[part 1 of 2: packages /MICROSAR/NvM_swc/DataTypes to /MICROSAR/NvM_swc/ComponentTypes]
AUTOSAR XML (schema 00044)
package /MICROSAR/NvM_swc/DataTypes
  impl type NvM_RequestResultType: compu {0=NVM_REQ_OK, 1=NVM_REQ_NOT_OK, 2=NVM_REQ_PENDING, 3=NVM_REQ_INTEGRITY_FAILED, 4=NVM_REQ_BLOCK_SKIPPED, 5=NVM_REQ_NV_INVALIDATED, 6=NVM_REQ_CANCELED, 7=NVM_REQ_REDUNDANCY_FAILED, 8=NVM_REQ_RESTORED_FROM_ROM}, range raw 0..8, implementation-data-type=uint8
  impl type NvM_BlockIdType: range raw 1..32767, implementation-data-type=uint16
  impl type NvM_ServiceIdType: compu {6=NVM_READ_BLOCK, 7=NVM_WRITE_BLOCK, 8=NVM_RESTORE_BLOCK_DEFAULTS, 9=NVM_ERASE_BLOCK, 11=NVM_INVALIDATE_NV_BLOCK, 12=NVM_READ_ALL}, range raw 6..12, implementation-data-type=uint8
package /MICROSAR/NvM_swc/Interfaces
  client server interface NvMAdministration: is-service=true, service-kind=NON-VOLATILE-RAM-MANAGER
    operation SetBlockProtection: possible-error=NvMAdministration/E_NOT_OK
      arg ProtectionEnabled: type=boolean, direction=IN
    error E_NOT_OK: error-code=1
  client server interface NvMService_AC3_SRBS_DS_Defs: is-service=true, service-kind=NON-VOLATILE-RAM-MANAGER
    9 x operation, all with possible-error=NvMService_AC3_SRBS_DS_Defs/E_NOT_OK:
      GetErrorStatus
        arg ErrorStatus: type=NvM_RequestResultType, direction=OUT
      SetRamBlockStatus
        arg RamBlockStatus: type=boolean, direction=IN
      ReadBlock
        arg DstPtr: type=dtRef_VOID, direction=IN
      WriteBlock
        arg SrcPtr: type=dtRef_const_VOID, direction=IN
      RestoreBlockDefaults
        arg DstPtr: type=dtRef_VOID, direction=IN
      SetDataIndex
        arg DataIndex: type=uint8, direction=IN
      GetDataIndex
        arg DataIndex: type=uint8, direction=OUT
      InvalidateNvBlock
      EraseBlock
    error E_NOT_OK: error-code=1
  client server interface NvMNotifyJobFinished: is-service=true, service-kind=NON-VOLATILE-RAM-MANAGER
    operation JobFinished
      arg ServiceId: type=NvM_ServiceIdType, direction=IN
      arg JobResult: type=NvM_RequestResultType, direction=IN
package /MICROSAR/NvM_swc/ComponentTypes
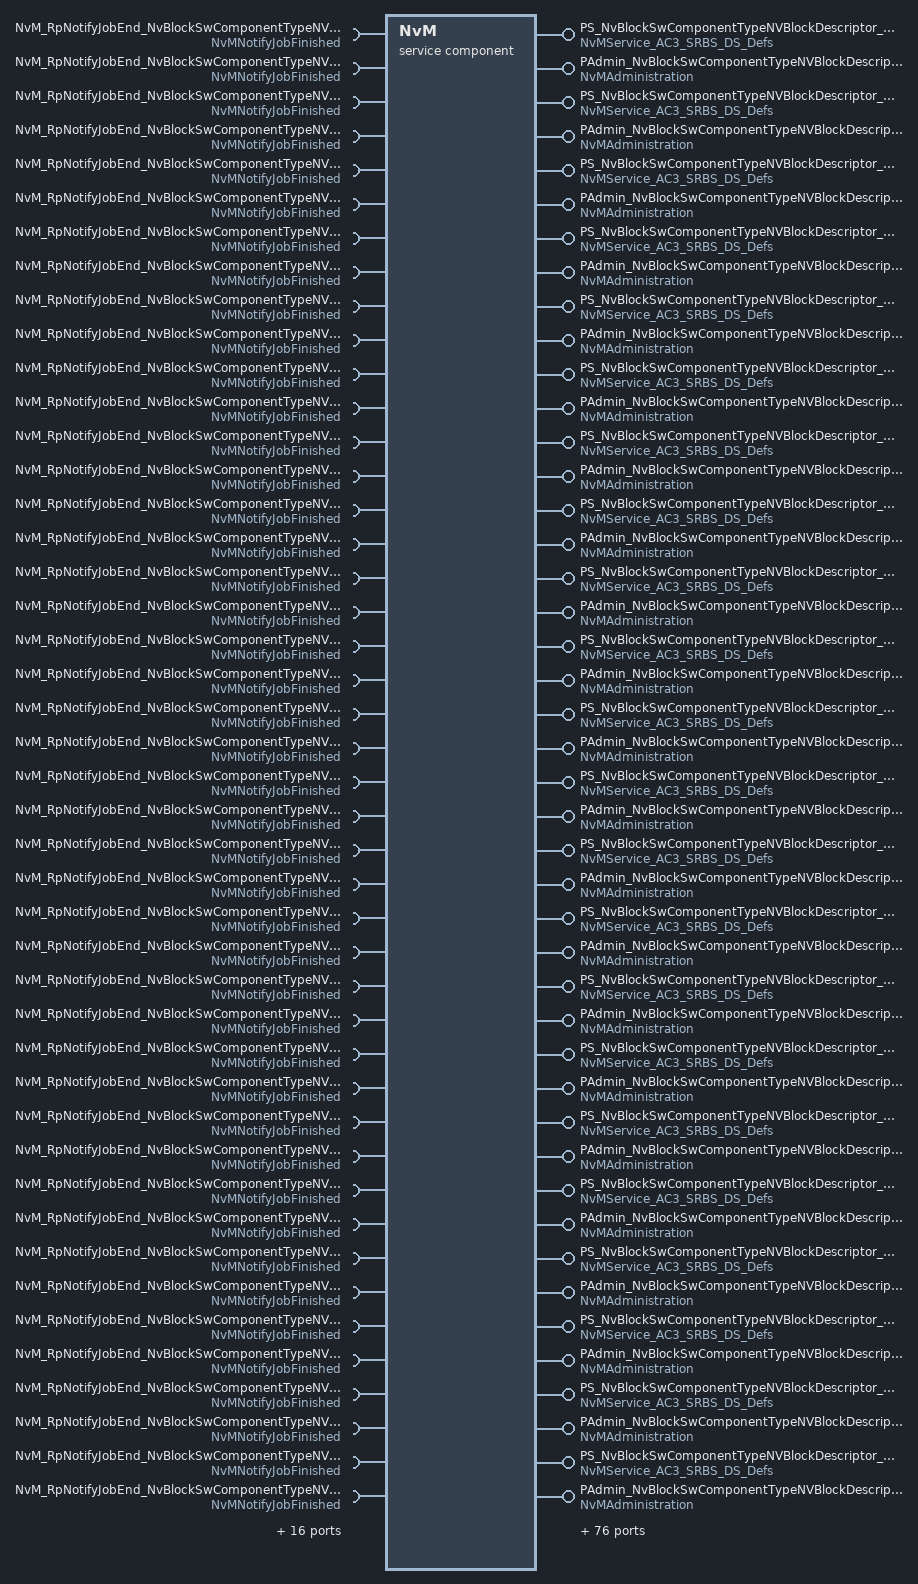
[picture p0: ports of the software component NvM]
  service sw component type NvM: category=SERVICE_COMPONENT
    120 x provide port:
      PS_NvBlockSwComponentTypeNVBlockDescriptor_BsConst_Audio: provided-interface=NvMService_AC3_SRBS_DS_Defs
      PAdmin_NvBlockSwComponentTypeNVBlockDescriptor_BsConst_Audio: provided-interface=NvMAdministration
      PS_NvBlockSwComponentTypeNVBlockDescriptor_BsConst_Communication: provided-interface=NvMService_AC3_SRBS_DS_Defs
      PAdmin_NvBlockSwComponentTypeNVBlockDescriptor_BsConst_Communication: provided-interface=NvMAdministration
      PS_NvBlockSwComponentTypeNVBlockDescriptor_BsConst_EngOffTimer: provided-interface=NvMService_AC3_SRBS_DS_Defs
      PAdmin_NvBlockSwComponentTypeNVBlockDescriptor_BsConst_EngOffTimer: provided-interface=NvMAdministration
      PS_NvBlockSwComponentTypeNVBlockDescriptor_BsConst_FuelGauge: provided-interface=NvMService_AC3_SRBS_DS_Defs
      PAdmin_NvBlockSwComponentTypeNVBlockDescriptor_BsConst_FuelGauge: provided-interface=NvMAdministration
      PS_NvBlockSwComponentTypeNVBlockDescriptor_BsConst_Illumination: provided-interface=NvMService_AC3_SRBS_DS_Defs
      PAdmin_NvBlockSwComponentTypeNVBlockDescriptor_BsConst_Illumination: provided-interface=NvMAdministration
      PS_NvBlockSwComponentTypeNVBlockDescriptor_BsConst_OilGauge: provided-interface=NvMService_AC3_SRBS_DS_Defs
      PAdmin_NvBlockSwComponentTypeNVBlockDescriptor_BsConst_OilGauge: provided-interface=NvMAdministration
      PS_NvBlockSwComponentTypeNVBlockDescriptor_BsConst_Power: provided-interface=NvMService_AC3_SRBS_DS_Defs
      PAdmin_NvBlockSwComponentTypeNVBlockDescriptor_BsConst_Power: provided-interface=NvMAdministration
      PS_NvBlockSwComponentTypeNVBlockDescriptor_BsConst_PowerGauge: provided-interface=NvMService_AC3_SRBS_DS_Defs
      PAdmin_NvBlockSwComponentTypeNVBlockDescriptor_BsConst_PowerGauge: provided-interface=NvMAdministration
      PS_NvBlockSwComponentTypeNVBlockDescriptor_BsConst_RealTimeClock: provided-interface=NvMService_AC3_SRBS_DS_Defs
      PAdmin_NvBlockSwComponentTypeNVBlockDescriptor_BsConst_RealTimeClock: provided-interface=NvMAdministration
      PS_NvBlockSwComponentTypeNVBlockDescriptor_BsConst_ServiceReminder: provided-interface=NvMService_AC3_SRBS_DS_Defs
      PAdmin_NvBlockSwComponentTypeNVBlockDescriptor_BsConst_ServiceReminder: provided-interface=NvMAdministration
      PS_NvBlockSwComponentTypeNVBlockDescriptor_BsConst_SpeedoGauge: provided-interface=NvMService_AC3_SRBS_DS_Defs
      PAdmin_NvBlockSwComponentTypeNVBlockDescriptor_BsConst_SpeedoGauge: provided-interface=NvMAdministration
      PS_NvBlockSwComponentTypeNVBlockDescriptor_BsConst_TachoGauge: provided-interface=NvMService_AC3_SRBS_DS_Defs
      PAdmin_NvBlockSwComponentTypeNVBlockDescriptor_BsConst_TachoGauge: provided-interface=NvMAdministration
      PS_NvBlockSwComponentTypeNVBlockDescriptor_BsConst_TempGauge: provided-interface=NvMService_AC3_SRBS_DS_Defs
      PAdmin_NvBlockSwComponentTypeNVBlockDescriptor_BsConst_TempGauge: provided-interface=NvMAdministration
      PS_NvBlockSwComponentTypeNVBlockDescriptor_BsConst_TripComputer: provided-interface=NvMService_AC3_SRBS_DS_Defs
      PAdmin_NvBlockSwComponentTypeNVBlockDescriptor_BsConst_TripComputer: provided-interface=NvMAdministration
      PS_NvBlockSwComponentTypeNVBlockDescriptor_BsConst_Warning: provided-interface=NvMService_AC3_SRBS_DS_Defs
      PAdmin_NvBlockSwComponentTypeNVBlockDescriptor_BsConst_Warning: provided-interface=NvMAdministration
      PS_NvBlockSwComponentTypeNVBlockDescriptor_BsCys_Certicificate: provided-interface=NvMService_AC3_SRBS_DS_Defs
      PAdmin_NvBlockSwComponentTypeNVBlockDescriptor_BsCys_Certicificate: provided-interface=NvMAdministration
      PS_NvBlockSwComponentTypeNVBlockDescriptor_BsDiag_Dtc: provided-interface=NvMService_AC3_SRBS_DS_Defs
      PAdmin_NvBlockSwComponentTypeNVBlockDescriptor_BsDiag_Dtc: provided-interface=NvMAdministration
      PS_NvBlockSwComponentTypeNVBlockDescriptor_BsDiag_ErrorRecord: provided-interface=NvMService_AC3_SRBS_DS_Defs
      PAdmin_NvBlockSwComponentTypeNVBlockDescriptor_BsDiag_ErrorRecord: provided-interface=NvMAdministration
      PS_NvBlockSwComponentTypeNVBlockDescriptor_BsFuSa_Audio: provided-interface=NvMService_AC3_SRBS_DS_Defs
      PAdmin_NvBlockSwComponentTypeNVBlockDescriptor_BsFuSa_Audio: provided-interface=NvMAdministration
      PS_NvBlockSwComponentTypeNVBlockDescriptor_BsFuSa_Communication: provided-interface=NvMService_AC3_SRBS_DS_Defs
      PAdmin_NvBlockSwComponentTypeNVBlockDescriptor_BsFuSa_Communication: provided-interface=NvMAdministration
      PS_NvBlockSwComponentTypeNVBlockDescriptor_BsFuSa_Config: provided-interface=NvMService_AC3_SRBS_DS_Defs
      PAdmin_NvBlockSwComponentTypeNVBlockDescriptor_BsFuSa_Config: provided-interface=NvMAdministration
      PS_NvBlockSwComponentTypeNVBlockDescriptor_BsFuSa_Display: provided-interface=NvMService_AC3_SRBS_DS_Defs
      PAdmin_NvBlockSwComponentTypeNVBlockDescriptor_BsFuSa_Display: provided-interface=NvMAdministration
      PS_NvBlockSwComponentTypeNVBlockDescriptor_BsFuSa_Power: provided-interface=NvMService_AC3_SRBS_DS_Defs
      PAdmin_NvBlockSwComponentTypeNVBlockDescriptor_BsFuSa_Power: provided-interface=NvMAdministration
      PS_NvBlockSwComponentTypeNVBlockDescriptor_BsFuSa_Warning: provided-interface=NvMService_AC3_SRBS_DS_Defs
      PAdmin_NvBlockSwComponentTypeNVBlockDescriptor_BsFuSa_Warning: provided-interface=NvMAdministration
      PS_NvBlockSwComponentTypeNVBlockDescriptor_BsFusa_Fota: provided-interface=NvMService_AC3_SRBS_DS_Defs
      PAdmin_NvBlockSwComponentTypeNVBlockDescriptor_BsFusa_Fota: provided-interface=NvMAdministration
      PS_NvBlockSwComponentTypeNVBlockDescriptor_BsReten_Audio: provided-interface=NvMService_AC3_SRBS_DS_Defs
      PAdmin_NvBlockSwComponentTypeNVBlockDescriptor_BsReten_Audio: provided-interface=NvMAdministration
      PS_NvBlockSwComponentTypeNVBlockDescriptor_BsReten_Communication: provided-interface=NvMService_AC3_SRBS_DS_Defs
      PAdmin_NvBlockSwComponentTypeNVBlockDescriptor_BsReten_Communication: provided-interface=NvMAdministration
      PS_NvBlockSwComponentTypeNVBlockDescriptor_BsReten_Display: provided-interface=NvMService_AC3_SRBS_DS_Defs
      PAdmin_NvBlockSwComponentTypeNVBlockDescriptor_BsReten_Display: provided-interface=NvMAdministration
      PS_NvBlockSwComponentTypeNVBlockDescriptor_BsReten_Gauges: provided-interface=NvMService_AC3_SRBS_DS_Defs
      PAdmin_NvBlockSwComponentTypeNVBlockDescriptor_BsReten_Gauges: provided-interface=NvMAdministration
      PS_NvBlockSwComponentTypeNVBlockDescriptor_BsReten_Illumination: provided-interface=NvMService_AC3_SRBS_DS_Defs
      PAdmin_NvBlockSwComponentTypeNVBlockDescriptor_BsReten_Illumination: provided-interface=NvMAdministration
      PS_NvBlockSwComponentTypeNVBlockDescriptor_BsReten_Odometer: provided-interface=NvMService_AC3_SRBS_DS_Defs
      PAdmin_NvBlockSwComponentTypeNVBlockDescriptor_BsReten_Odometer: provided-interface=NvMAdministration
      PS_NvBlockSwComponentTypeNVBlockDescriptor_BsReten_Personalization: provided-interface=NvMService_AC3_SRBS_DS_Defs
      PAdmin_NvBlockSwComponentTypeNVBlockDescriptor_BsReten_Personalization: provided-interface=NvMAdministration
      PS_NvBlockSwComponentTypeNVBlockDescriptor_BsReten_Power: provided-interface=NvMService_AC3_SRBS_DS_Defs
      PAdmin_NvBlockSwComponentTypeNVBlockDescriptor_BsReten_Power: provided-interface=NvMAdministration
      PS_NvBlockSwComponentTypeNVBlockDescriptor_BsReten_RealTimeClock: provided-interface=NvMService_AC3_SRBS_DS_Defs
      PAdmin_NvBlockSwComponentTypeNVBlockDescriptor_BsReten_RealTimeClock: provided-interface=NvMAdministration
      PS_NvBlockSwComponentTypeNVBlockDescriptor_BsReten_Tripcomputer: provided-interface=NvMService_AC3_SRBS_DS_Defs
      PAdmin_NvBlockSwComponentTypeNVBlockDescriptor_BsReten_Tripcomputer: provided-interface=NvMAdministration
      PS_NvBlockSwComponentTypeNVBlockDescriptor_BsReten_VisDlt: provided-interface=NvMService_AC3_SRBS_DS_Defs
      PAdmin_NvBlockSwComponentTypeNVBlockDescriptor_BsReten_VisDlt: provided-interface=NvMAdministration
      PS_NvBlockSwComponentTypeNVBlockDescriptor_BsReten_Warning: provided-interface=NvMService_AC3_SRBS_DS_Defs
      PAdmin_NvBlockSwComponentTypeNVBlockDescriptor_BsReten_Warning: provided-interface=NvMAdministration
      PS_NvBlockSwComponentTypeNVBlockDescriptor_BsRt_CusDlt: provided-interface=NvMService_AC3_SRBS_DS_Defs
      PAdmin_NvBlockSwComponentTypeNVBlockDescriptor_BsRt_CusDlt: provided-interface=NvMAdministration
      PS_NvBlockSwComponentTypeNVBlockDescriptor_BsRt_FuelGauge: provided-interface=NvMService_AC3_SRBS_DS_Defs
      PAdmin_NvBlockSwComponentTypeNVBlockDescriptor_BsRt_FuelGauge: provided-interface=NvMAdministration
      PS_NvBlockSwComponentTypeNVBlockDescriptor_BsRt_Illumination: provided-interface=NvMService_AC3_SRBS_DS_Defs
      PAdmin_NvBlockSwComponentTypeNVBlockDescriptor_BsRt_Illumination: provided-interface=NvMAdministration
      PS_NvBlockSwComponentTypeNVBlockDescriptor_BsRt_Odometer: provided-interface=NvMService_AC3_SRBS_DS_Defs
      PAdmin_NvBlockSwComponentTypeNVBlockDescriptor_BsRt_Odometer: provided-interface=NvMAdministration
      PS_NvBlockSwComponentTypeNVBlockDescriptor_BsRt_OilGauge: provided-interface=NvMService_AC3_SRBS_DS_Defs
      PAdmin_NvBlockSwComponentTypeNVBlockDescriptor_BsRt_OilGauge: provided-interface=NvMAdministration
      PS_NvBlockSwComponentTypeNVBlockDescriptor_BsRt_Personalization: provided-interface=NvMService_AC3_SRBS_DS_Defs
      PAdmin_NvBlockSwComponentTypeNVBlockDescriptor_BsRt_Personalization: provided-interface=NvMAdministration
      PS_NvBlockSwComponentTypeNVBlockDescriptor_BsRt_PowerGauge: provided-interface=NvMService_AC3_SRBS_DS_Defs
      PAdmin_NvBlockSwComponentTypeNVBlockDescriptor_BsRt_PowerGauge: provided-interface=NvMAdministration
      PS_NvBlockSwComponentTypeNVBlockDescriptor_BsRt_RealTimeClock: provided-interface=NvMService_AC3_SRBS_DS_Defs
      PAdmin_NvBlockSwComponentTypeNVBlockDescriptor_BsRt_RealTimeClock: provided-interface=NvMAdministration
      PS_NvBlockSwComponentTypeNVBlockDescriptor_BsRt_SpeedoGauge: provided-interface=NvMService_AC3_SRBS_DS_Defs
      PAdmin_NvBlockSwComponentTypeNVBlockDescriptor_BsRt_SpeedoGauge: provided-interface=NvMAdministration
      PS_NvBlockSwComponentTypeNVBlockDescriptor_BsRt_TachoGauge: provided-interface=NvMService_AC3_SRBS_DS_Defs
      PAdmin_NvBlockSwComponentTypeNVBlockDescriptor_BsRt_TachoGauge: provided-interface=NvMAdministration
      PS_NvBlockSwComponentTypeNVBlockDescriptor_BsRt_TempGauge: provided-interface=NvMService_AC3_SRBS_DS_Defs
      PAdmin_NvBlockSwComponentTypeNVBlockDescriptor_BsRt_TempGauge: provided-interface=NvMAdministration
      PS_NvBlockSwComponentTypeNVBlockDescriptor_BsRt_TripComputer: provided-interface=NvMService_AC3_SRBS_DS_Defs
      PAdmin_NvBlockSwComponentTypeNVBlockDescriptor_BsRt_TripComputer: provided-interface=NvMAdministration
      PS_NvBlockSwComponentTypeNVBlockDescriptor_BsRt_Warning: provided-interface=NvMService_AC3_SRBS_DS_Defs
      PAdmin_NvBlockSwComponentTypeNVBlockDescriptor_BsRt_Warning: provided-interface=NvMAdministration
      PS_NvBlockSwComponentTypeNVBlockDescriptor_BsShare_EcuPartNumber: provided-interface=NvMService_AC3_SRBS_DS_Defs
      PAdmin_NvBlockSwComponentTypeNVBlockDescriptor_BsShare_EcuPartNumber: provided-interface=NvMAdministration
      PS_NvBlockSwComponentTypeNVBlockDescriptor_BsShare_SwUpdFotaFinPrint: provided-interface=NvMService_AC3_SRBS_DS_Defs
      PAdmin_NvBlockSwComponentTypeNVBlockDescriptor_BsShare_SwUpdFotaFinPrint: provided-interface=NvMAdministration
      PS_NvBlockSwComponentTypeNVBlockDescriptor_BsShare_SwUpdFotaMode: provided-interface=NvMService_AC3_SRBS_DS_Defs
      PAdmin_NvBlockSwComponentTypeNVBlockDescriptor_BsShare_SwUpdFotaMode: provided-interface=NvMAdministration
      PS_NvBlockSwComponentTypeNVBlockDescriptor_BsShare_SwUpdFotaStatus: provided-interface=NvMService_AC3_SRBS_DS_Defs
      PAdmin_NvBlockSwComponentTypeNVBlockDescriptor_BsShare_SwUpdFotaStatus: provided-interface=NvMAdministration
      PS_NvBlockSwComponentTypeNVBlockDescriptor_BsShare_SwUpdFotadecrypt: provided-interface=NvMService_AC3_SRBS_DS_Defs
      PAdmin_NvBlockSwComponentTypeNVBlockDescriptor_BsShare_SwUpdFotadecrypt: provided-interface=NvMAdministration
      PS_NvBlockSwComponentTypeNVBlockDescriptor_BsShare_SwUpdReflash: provided-interface=NvMService_AC3_SRBS_DS_Defs
      PAdmin_NvBlockSwComponentTypeNVBlockDescriptor_BsShare_SwUpdReflash: provided-interface=NvMAdministration
      PS_NvBlockSwComponentTypeNVBlockDescriptor_BsShare_VehicleConfig: provided-interface=NvMService_AC3_SRBS_DS_Defs
      PAdmin_NvBlockSwComponentTypeNVBlockDescriptor_BsShare_VehicleConfig: provided-interface=NvMAdministration
      PS_NvBlockSwComponentTypeNVBlockDescriptor_BsShare_VisMeet: provided-interface=NvMService_AC3_SRBS_DS_Defs
      PAdmin_NvBlockSwComponentTypeNVBlockDescriptor_BsShare_VisMeet: provided-interface=NvMAdministration
      PS_NvBlockSwComponentTypeNVBlockDescriptor_RefCys_Certicificate: provided-interface=NvMService_AC3_SRBS_DS_Defs
      PAdmin_NvBlockSwComponentTypeNVBlockDescriptor_RefCys_Certicificate: provided-interface=NvMAdministration
      PS_NvBlockSwComponentTypeNVBlockDescriptor_RefCys_Certicificate1: provided-interface=NvMService_AC3_SRBS_DS_Defs
      PAdmin_NvBlockSwComponentTypeNVBlockDescriptor_RefCys_Certicificate1: provided-interface=NvMAdministration
    60 x require port, all with required-interface=NvMNotifyJobFinished:
      NvM_RpNotifyJobEnd_NvBlockSwComponentTypeNVBlockDescriptor_BsConst_Audio
      NvM_RpNotifyJobEnd_NvBlockSwComponentTypeNVBlockDescriptor_BsConst_Communication
      NvM_RpNotifyJobEnd_NvBlockSwComponentTypeNVBlockDescriptor_BsConst_EngOffTimer
      NvM_RpNotifyJobEnd_NvBlockSwComponentTypeNVBlockDescriptor_BsConst_FuelGauge
      NvM_RpNotifyJobEnd_NvBlockSwComponentTypeNVBlockDescriptor_BsConst_Illumination
      NvM_RpNotifyJobEnd_NvBlockSwComponentTypeNVBlockDescriptor_BsConst_OilGauge
      NvM_RpNotifyJobEnd_NvBlockSwComponentTypeNVBlockDescriptor_BsConst_Power
      NvM_RpNotifyJobEnd_NvBlockSwComponentTypeNVBlockDescriptor_BsConst_PowerGauge
      NvM_RpNotifyJobEnd_NvBlockSwComponentTypeNVBlockDescriptor_BsConst_RealTimeClock
      NvM_RpNotifyJobEnd_NvBlockSwComponentTypeNVBlockDescriptor_BsConst_ServiceReminder
      NvM_RpNotifyJobEnd_NvBlockSwComponentTypeNVBlockDescriptor_BsConst_SpeedoGauge
      NvM_RpNotifyJobEnd_NvBlockSwComponentTypeNVBlockDescriptor_BsConst_TachoGauge
      NvM_RpNotifyJobEnd_NvBlockSwComponentTypeNVBlockDescriptor_BsConst_TempGauge
      NvM_RpNotifyJobEnd_NvBlockSwComponentTypeNVBlockDescriptor_BsConst_TripComputer
      NvM_RpNotifyJobEnd_NvBlockSwComponentTypeNVBlockDescriptor_BsConst_Warning
      NvM_RpNotifyJobEnd_NvBlockSwComponentTypeNVBlockDescriptor_BsCys_Certicificate
      NvM_RpNotifyJobEnd_NvBlockSwComponentTypeNVBlockDescriptor_BsDiag_Dtc
      NvM_RpNotifyJobEnd_NvBlockSwComponentTypeNVBlockDescriptor_BsDiag_ErrorRecord
      NvM_RpNotifyJobEnd_NvBlockSwComponentTypeNVBlockDescriptor_BsFuSa_Audio
      NvM_RpNotifyJobEnd_NvBlockSwComponentTypeNVBlockDescriptor_BsFuSa_Communication
      NvM_RpNotifyJobEnd_NvBlockSwComponentTypeNVBlockDescriptor_BsFuSa_Config
      NvM_RpNotifyJobEnd_NvBlockSwComponentTypeNVBlockDescriptor_BsFuSa_Display
      NvM_RpNotifyJobEnd_NvBlockSwComponentTypeNVBlockDescriptor_BsFuSa_Power
      NvM_RpNotifyJobEnd_NvBlockSwComponentTypeNVBlockDescriptor_BsFuSa_Warning
      NvM_RpNotifyJobEnd_NvBlockSwComponentTypeNVBlockDescriptor_BsFusa_Fota
      NvM_RpNotifyJobEnd_NvBlockSwComponentTypeNVBlockDescriptor_BsReten_Audio
      NvM_RpNotifyJobEnd_NvBlockSwComponentTypeNVBlockDescriptor_BsReten_Communication
      NvM_RpNotifyJobEnd_NvBlockSwComponentTypeNVBlockDescriptor_BsReten_Display
      NvM_RpNotifyJobEnd_NvBlockSwComponentTypeNVBlockDescriptor_BsReten_Gauges
      NvM_RpNotifyJobEnd_NvBlockSwComponentTypeNVBlockDescriptor_BsReten_Illumination
      NvM_RpNotifyJobEnd_NvBlockSwComponentTypeNVBlockDescriptor_BsReten_Odometer
      NvM_RpNotifyJobEnd_NvBlockSwComponentTypeNVBlockDescriptor_BsReten_Personalization
      NvM_RpNotifyJobEnd_NvBlockSwComponentTypeNVBlockDescriptor_BsReten_Power
      NvM_RpNotifyJobEnd_NvBlockSwComponentTypeNVBlockDescriptor_BsReten_RealTimeClock
      NvM_RpNotifyJobEnd_NvBlockSwComponentTypeNVBlockDescriptor_BsReten_Tripcomputer
      NvM_RpNotifyJobEnd_NvBlockSwComponentTypeNVBlockDescriptor_BsReten_VisDlt
      NvM_RpNotifyJobEnd_NvBlockSwComponentTypeNVBlockDescriptor_BsReten_Warning
      NvM_RpNotifyJobEnd_NvBlockSwComponentTypeNVBlockDescriptor_BsRt_CusDlt
      NvM_RpNotifyJobEnd_NvBlockSwComponentTypeNVBlockDescriptor_BsRt_FuelGauge
      NvM_RpNotifyJobEnd_NvBlockSwComponentTypeNVBlockDescriptor_BsRt_Illumination
      NvM_RpNotifyJobEnd_NvBlockSwComponentTypeNVBlockDescriptor_BsRt_Odometer
      NvM_RpNotifyJobEnd_NvBlockSwComponentTypeNVBlockDescriptor_BsRt_OilGauge
      NvM_RpNotifyJobEnd_NvBlockSwComponentTypeNVBlockDescriptor_BsRt_Personalization
      NvM_RpNotifyJobEnd_NvBlockSwComponentTypeNVBlockDescriptor_BsRt_PowerGauge
      NvM_RpNotifyJobEnd_NvBlockSwComponentTypeNVBlockDescriptor_BsRt_RealTimeClock
      NvM_RpNotifyJobEnd_NvBlockSwComponentTypeNVBlockDescriptor_BsRt_SpeedoGauge
      NvM_RpNotifyJobEnd_NvBlockSwComponentTypeNVBlockDescriptor_BsRt_TachoGauge
      NvM_RpNotifyJobEnd_NvBlockSwComponentTypeNVBlockDescriptor_BsRt_TempGauge
      NvM_RpNotifyJobEnd_NvBlockSwComponentTypeNVBlockDescriptor_BsRt_TripComputer
      NvM_RpNotifyJobEnd_NvBlockSwComponentTypeNVBlockDescriptor_BsRt_Warning
      NvM_RpNotifyJobEnd_NvBlockSwComponentTypeNVBlockDescriptor_BsShare_EcuPartNumber
      NvM_RpNotifyJobEnd_NvBlockSwComponentTypeNVBlockDescriptor_BsShare_SwUpdFotaFinPrint
      NvM_RpNotifyJobEnd_NvBlockSwComponentTypeNVBlockDescriptor_BsShare_SwUpdFotaMode
      NvM_RpNotifyJobEnd_NvBlockSwComponentTypeNVBlockDescriptor_BsShare_SwUpdFotaStatus
      NvM_RpNotifyJobEnd_NvBlockSwComponentTypeNVBlockDescriptor_BsShare_SwUpdFotadecrypt
      NvM_RpNotifyJobEnd_NvBlockSwComponentTypeNVBlockDescriptor_BsShare_SwUpdReflash
      NvM_RpNotifyJobEnd_NvBlockSwComponentTypeNVBlockDescriptor_BsShare_VehicleConfig
      NvM_RpNotifyJobEnd_NvBlockSwComponentTypeNVBlockDescriptor_BsShare_VisMeet
      NvM_RpNotifyJobEnd_NvBlockSwComponentTypeNVBlockDescriptor_RefCys_Certicificate
      NvM_RpNotifyJobEnd_NvBlockSwComponentTypeNVBlockDescriptor_RefCys_Certicificate1
